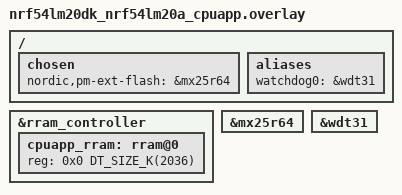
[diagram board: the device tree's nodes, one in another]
/*
 * Copyright (c) 2025 Nordic Semiconductor ASA
 *
 * SPDX-License-Identifier: LicenseRef-Nordic-5-Clause
 */

/ {
	chosen {
		nordic,pm-ext-flash = &mx25r64;
	};

	aliases {
		/* Use watchdog wdt31 as the application watchdog */
		watchdog0 = &wdt31;
	};
};

&rram_controller {
	cpuapp_rram: rram@0 {
		reg = <0x0 DT_SIZE_K(2036)>;
		ranges = <0x0 0x0 DT_SIZE_K(2036)>;
	};
};

&mx25r64 {
	status = "okay";
};

&wdt31 {
	status = "okay";
};
